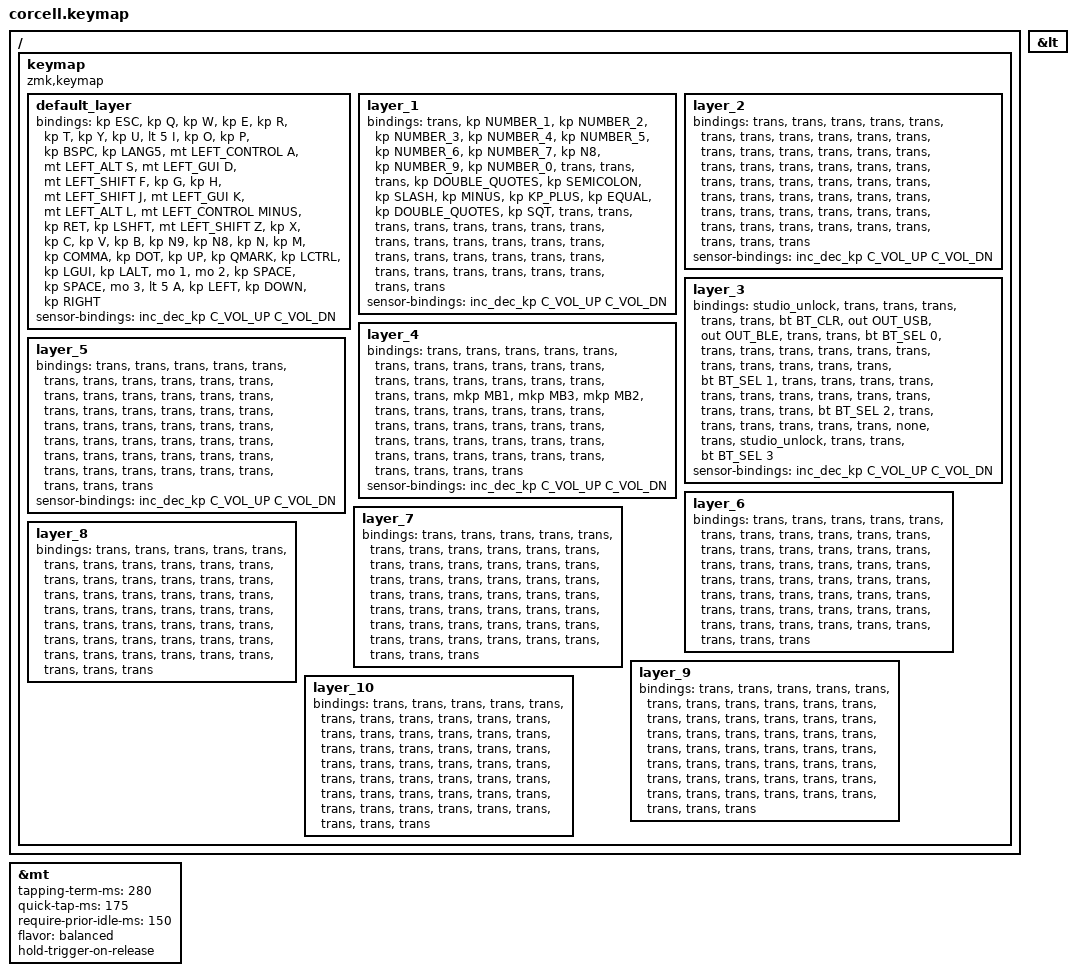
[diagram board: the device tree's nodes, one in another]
#include <dt-bindings/zmk/mouse.h>
#include <behaviors/runtime-input-processor.dtsi>
#include <behaviors.dtsi>
#include <dt-bindings/zmk/bt.h>
#include <dt-bindings/zmk/keys.h>
#include <dt-bindings/zmk/outputs.h>
#include <dt-bindings/zmk/pointing.h>

&mt {
    tapping-term-ms = <280>;
    quick-tap-ms = <175>;
    require-prior-idle-ms = <150>;
    flavor = "balanced";
    hold-trigger-on-release;
};

&lt {
};

/ {
    keymap {
        compatible = "zmk,keymap";

        default_layer {
            bindings = <
&kp ESC  &kp Q  &kp W  &kp E  &kp R  &kp T  &kp Y  &kp U  &lt 5 I  &kp O  &kp P  &kp BSPC  &kp LANG5  &mt LEFT_CONTROL A  &mt LEFT_ALT S  &mt LEFT_GUI D  &mt LEFT_SHIFT F  &kp G  &kp H  &mt LEFT_SHIFT J  &mt LEFT_GUI K  &mt LEFT_ALT L  &mt LEFT_CONTROL MINUS  &kp RET  &kp LSHFT  &mt LEFT_SHIFT Z  &kp X  &kp C  &kp V  &kp B  &kp N9  &kp N8  &kp N  &kp M  &kp COMMA  &kp DOT  &kp UP  &kp QMARK  &kp LCTRL  &kp LGUI  &kp LALT  &mo 1  &mo 2  &kp SPACE  &kp SPACE  &mo 3  &lt 5 A  &kp LEFT  &kp DOWN  &kp RIGHT
            >;

            sensor-bindings = <&inc_dec_kp C_VOL_UP C_VOL_DN>;
        };

        layer_1 {
            bindings = <
&trans  &kp NUMBER_1  &kp NUMBER_2  &kp NUMBER_3  &kp NUMBER_4  &kp NUMBER_5  &kp NUMBER_6  &kp NUMBER_7  &kp N8  &kp NUMBER_9  &kp NUMBER_0  &trans  &trans  &trans  &kp DOUBLE_QUOTES  &kp SEMICOLON  &kp SLASH  &kp MINUS  &kp KP_PLUS  &kp EQUAL  &kp DOUBLE_QUOTES  &kp SQT  &trans  &trans  &trans  &trans  &trans  &trans  &trans  &trans  &trans  &trans  &trans  &trans  &trans  &trans  &trans  &trans  &trans  &trans  &trans  &trans  &trans  &trans  &trans  &trans  &trans  &trans  &trans  &trans
            >;

            sensor-bindings = <&inc_dec_kp C_VOL_UP C_VOL_DN>;
        };

        layer_2 {
            bindings = <
&trans  &trans  &trans  &trans  &trans  &trans  &trans  &trans  &trans  &trans  &trans  &trans  &trans  &trans  &trans  &trans  &trans  &trans  &trans  &trans  &trans  &trans  &trans  &trans  &trans  &trans  &trans  &trans  &trans  &trans  &trans  &trans  &trans  &trans  &trans  &trans  &trans  &trans  &trans  &trans  &trans  &trans  &trans  &trans  &trans  &trans  &trans  &trans  &trans  &trans
            >;

            sensor-bindings = <&inc_dec_kp C_VOL_UP C_VOL_DN>;
        };

        // Connection controls are reachable using only the central (right) half.

        layer_3 {
            bindings = <
&studio_unlock  &trans  &trans  &trans  &trans  &trans  &bt BT_CLR  &out OUT_USB  &out OUT_BLE  &trans  &trans  &bt BT_SEL 0  &trans  &trans  &trans  &trans  &trans  &trans  &trans  &trans  &trans  &trans  &trans  &bt BT_SEL 1  &trans  &trans  &trans  &trans  &trans  &trans  &trans  &trans  &trans  &trans  &trans  &trans  &trans  &bt BT_SEL 2  &trans  &trans  &trans  &trans  &trans  &trans  &none  &trans  &studio_unlock  &trans  &trans  &bt BT_SEL 3
            >;

            sensor-bindings = <&inc_dec_kp C_VOL_UP C_VOL_DN>;
        };

        layer_4 {
            bindings = <
&trans  &trans  &trans  &trans  &trans  &trans  &trans  &trans  &trans  &trans  &trans  &trans  &trans  &trans  &trans  &trans  &trans  &trans  &trans  &mkp MB1  &mkp MB3  &mkp MB2  &trans  &trans  &trans  &trans  &trans  &trans  &trans  &trans  &trans  &trans  &trans  &trans  &trans  &trans  &trans  &trans  &trans  &trans  &trans  &trans  &trans  &trans  &trans  &trans  &trans  &trans  &trans  &trans
            >;

            sensor-bindings = <&inc_dec_kp C_VOL_UP C_VOL_DN>;
        };

        layer_5 {
            bindings = <
&trans  &trans  &trans  &trans  &trans  &trans  &trans  &trans  &trans  &trans  &trans  &trans  &trans  &trans  &trans  &trans  &trans  &trans  &trans  &trans  &trans  &trans  &trans  &trans  &trans  &trans  &trans  &trans  &trans  &trans  &trans  &trans  &trans  &trans  &trans  &trans  &trans  &trans  &trans  &trans  &trans  &trans  &trans  &trans  &trans  &trans  &trans  &trans  &trans  &trans
            >;

            sensor-bindings = <&inc_dec_kp C_VOL_UP C_VOL_DN>;
        };

        layer_6 {
            bindings = <
&trans  &trans  &trans  &trans  &trans  &trans  &trans  &trans  &trans  &trans  &trans  &trans  &trans  &trans  &trans  &trans  &trans  &trans  &trans  &trans  &trans  &trans  &trans  &trans  &trans  &trans  &trans  &trans  &trans  &trans  &trans  &trans  &trans  &trans  &trans  &trans  &trans  &trans  &trans  &trans  &trans  &trans  &trans  &trans  &trans  &trans  &trans  &trans  &trans  &trans
            >;
        };

        layer_7 {
            bindings = <
&trans  &trans  &trans  &trans  &trans  &trans  &trans  &trans  &trans  &trans  &trans  &trans  &trans  &trans  &trans  &trans  &trans  &trans  &trans  &trans  &trans  &trans  &trans  &trans  &trans  &trans  &trans  &trans  &trans  &trans  &trans  &trans  &trans  &trans  &trans  &trans  &trans  &trans  &trans  &trans  &trans  &trans  &trans  &trans  &trans  &trans  &trans  &trans  &trans  &trans
            >;
        };

        layer_8 {
            bindings = <
&trans  &trans  &trans  &trans  &trans  &trans  &trans  &trans  &trans  &trans  &trans  &trans  &trans  &trans  &trans  &trans  &trans  &trans  &trans  &trans  &trans  &trans  &trans  &trans  &trans  &trans  &trans  &trans  &trans  &trans  &trans  &trans  &trans  &trans  &trans  &trans  &trans  &trans  &trans  &trans  &trans  &trans  &trans  &trans  &trans  &trans  &trans  &trans  &trans  &trans
            >;
        };

        layer_9 {
            bindings = <
&trans  &trans  &trans  &trans  &trans  &trans  &trans  &trans  &trans  &trans  &trans  &trans  &trans  &trans  &trans  &trans  &trans  &trans  &trans  &trans  &trans  &trans  &trans  &trans  &trans  &trans  &trans  &trans  &trans  &trans  &trans  &trans  &trans  &trans  &trans  &trans  &trans  &trans  &trans  &trans  &trans  &trans  &trans  &trans  &trans  &trans  &trans  &trans  &trans  &trans
            >;
        };

        layer_10 {
            bindings = <
&trans  &trans  &trans  &trans  &trans  &trans  &trans  &trans  &trans  &trans  &trans  &trans  &trans  &trans  &trans  &trans  &trans  &trans  &trans  &trans  &trans  &trans  &trans  &trans  &trans  &trans  &trans  &trans  &trans  &trans  &trans  &trans  &trans  &trans  &trans  &trans  &trans  &trans  &trans  &trans  &trans  &trans  &trans  &trans  &trans  &trans  &trans  &trans  &trans  &trans
            >;
        };
    };
};
